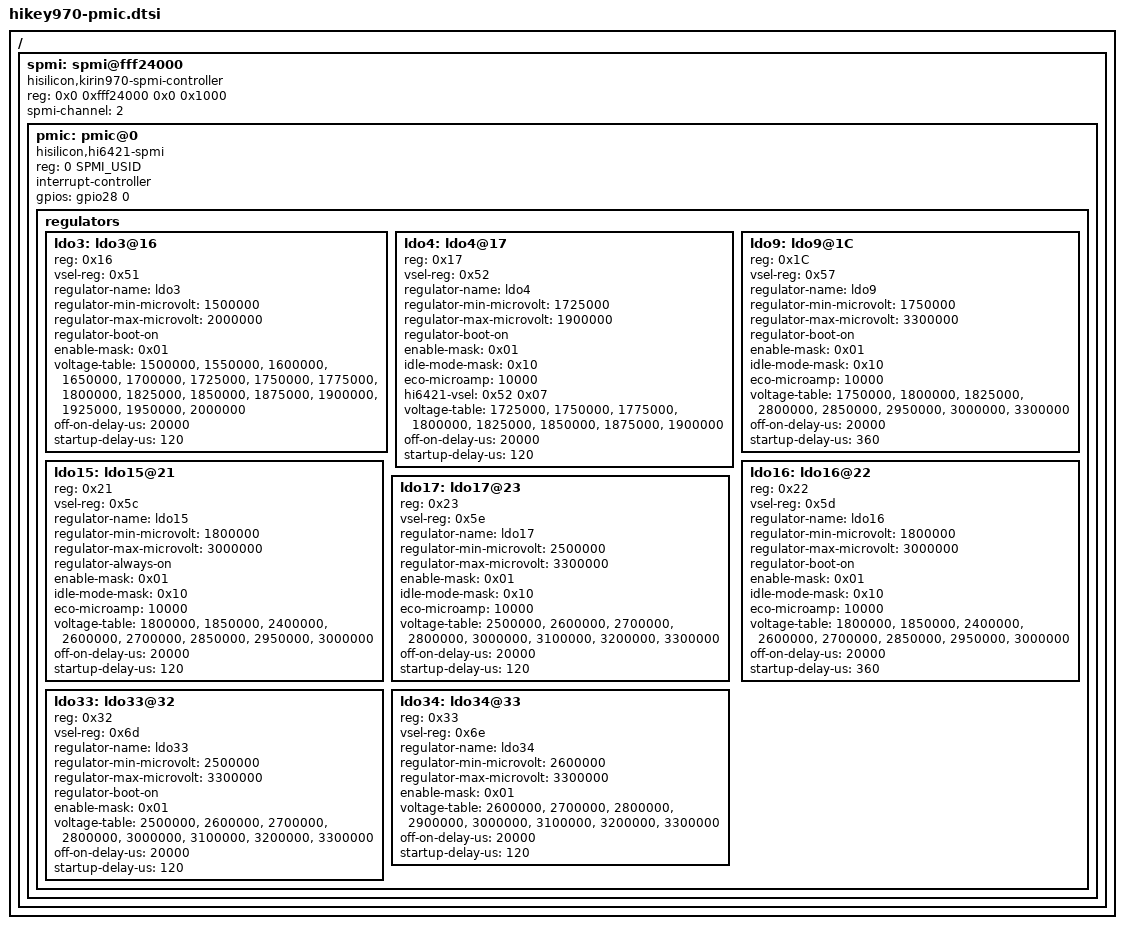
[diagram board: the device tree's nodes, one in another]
// SPDX-License-Identifier: GPL-2.0
/*
 * dts file for Hi6421v600 SPMI PMIC used at the HiKey970 Development Board
 *
 * Copyright (C) 2020, Huawei Tech. Co., Ltd.
 */

#include <dt-bindings/spmi/spmi.h>

/ {
	spmi: spmi@fff24000 {
		compatible = "hisilicon,kirin970-spmi-controller";
		#address-cells = <2>;
		#size-cells = <0>;
		status = "ok";
		reg = <0x0 0xfff24000 0x0 0x1000>;
		spmi-channel = <2>;

		pmic: pmic@0 {
			compatible = "hisilicon,hi6421-spmi";
			reg = <0 SPMI_USID>;

			#interrupt-cells = <2>;
			interrupt-controller;
			gpios = <&gpio28 0 0>;

			regulators {
				#address-cells = <1>;
				#size-cells = <0>;

				ldo3: ldo3@16 {
					reg = <0x16>;
					vsel-reg = <0x51>;

					regulator-name = "ldo3";
					regulator-min-microvolt = <1500000>;
					regulator-max-microvolt = <2000000>;
					regulator-boot-on;

					enable-mask = <0x01>;

					voltage-table = <1500000>, <1550000>,
							<1600000>, <1650000>,
							<1700000>, <1725000>,
							<1750000>, <1775000>,
							<1800000>, <1825000>,
							<1850000>, <1875000>,
							<1900000>, <1925000>,
							<1950000>, <2000000>;
					off-on-delay-us = <20000>;
					startup-delay-us = <120>;
				};

				ldo4: ldo4@17 { /* 40 PIN */
					reg = <0x17>;
					vsel-reg = <0x52>;

					regulator-name = "ldo4";
					regulator-min-microvolt = <1725000>;
					regulator-max-microvolt = <1900000>;
					regulator-boot-on;

					enable-mask = <0x01>;
					idle-mode-mask = <0x10>;
					eco-microamp = <10000>;

					hi6421-vsel = <0x52 0x07>;
					voltage-table = <1725000>, <1750000>,
							<1775000>, <1800000>,
							<1825000>, <1850000>,
							<1875000>, <1900000>;
					off-on-delay-us = <20000>;
					startup-delay-us = <120>;
				};

				ldo9: ldo9@1C { /* SDCARD I/O */
					reg = <0x1C>;
					vsel-reg = <0x57>;

					regulator-name = "ldo9";
					regulator-min-microvolt = <1750000>;
					regulator-max-microvolt = <3300000>;
					regulator-boot-on;

					enable-mask = <0x01>;
					idle-mode-mask = <0x10>;
					eco-microamp = <10000>;

					voltage-table = <1750000>, <1800000>,
							<1825000>, <2800000>,
							<2850000>, <2950000>,
							<3000000>, <3300000>;
					off-on-delay-us = <20000>;
					startup-delay-us = <360>;
				};

				ldo15: ldo15@21 { /* UFS */
					reg = <0x21>;
					vsel-reg = <0x5c>;

					regulator-name = "ldo15";
					regulator-min-microvolt = <1800000>;
					regulator-max-microvolt = <3000000>;
					regulator-always-on;

					enable-mask = <0x01>;
					idle-mode-mask = <0x10>;
					eco-microamp = <10000>;

					voltage-table = <1800000>, <1850000>,
							<2400000>, <2600000>,
							<2700000>, <2850000>,
							<2950000>, <3000000>;
					off-on-delay-us = <20000>;
					startup-delay-us = <120>;
				};

				ldo16: ldo16@22 { /* SD */
					reg = <0x22>;
					vsel-reg = <0x5d>;

					regulator-name = "ldo16";
					regulator-min-microvolt = <1800000>;
					regulator-max-microvolt = <3000000>;
					regulator-boot-on;

					enable-mask = <0x01>;
					idle-mode-mask = <0x10>;
					eco-microamp = <10000>;

					voltage-table = <1800000>, <1850000>,
							<2400000>, <2600000>,
							<2700000>, <2850000>,
							<2950000>, <3000000>;
					off-on-delay-us = <20000>;
					startup-delay-us = <360>;
				};

				ldo17: ldo17@23 {
					reg = <0x23>;
					vsel-reg = <0x5e>;

					regulator-name = "ldo17";
					regulator-min-microvolt = <2500000>;
					regulator-max-microvolt = <3300000>;

					enable-mask = <0x01>;
					idle-mode-mask = <0x10>;
					eco-microamp = <10000>;

					voltage-table = <2500000>, <2600000>,
							<2700000>, <2800000>,
							<3000000>, <3100000>,
							<3200000>, <3300000>;
					off-on-delay-us = <20000>;
					startup-delay-us = <120>;
				};

				ldo33: ldo33@32 { /* PEX8606 */
					reg = <0x32>;
					vsel-reg = <0x6d>;
					regulator-name = "ldo33";
					regulator-min-microvolt = <2500000>;
					regulator-max-microvolt = <3300000>;
					regulator-boot-on;

					enable-mask = <0x01>;

					voltage-table = <2500000>, <2600000>,
							<2700000>, <2800000>,
							<3000000>, <3100000>,
							<3200000>, <3300000>;
					off-on-delay-us = <20000>;
					startup-delay-us = <120>;
				};

				ldo34: ldo34@33 { /* GPS AUX IN VDD */
					reg = <0x33>;
					vsel-reg = <0x6e>;

					regulator-name = "ldo34";
					regulator-min-microvolt = <2600000>;
					regulator-max-microvolt = <3300000>;

					enable-mask = <0x01>;

					voltage-table = <2600000>, <2700000>,
							<2800000>, <2900000>,
							<3000000>, <3100000>,
							<3200000>, <3300000>;
					off-on-delay-us = <20000>;
					startup-delay-us = <120>;
				};
			};
		};
	};
};
